# TC100 register map
Vendor: TestCorp; File version: 1.0
Test Device TC100
Registers are 32-bit, read-write, reset 0x0 unless marked. A register's access mark holds for its fields unless they carry their own. Offsets are from the block's base; lines under a group give offsets from that group; [hi:lo] are bit positions; {n}, {i} and the like mark numbered series; 'fields as' and 'values as' point back to an identical list; <NAME> marks a mode.

## Memory map
0x40000000 TIMER0 — General Purpose Timer
0x40020000 DMA — DMA Controller
0x48000000 GPIOA — General-purpose I/O Port A
0x48000400 GPIOB — General-purpose I/O Port B

## TIMER0 — General Purpose Timer
Base 0x40000000
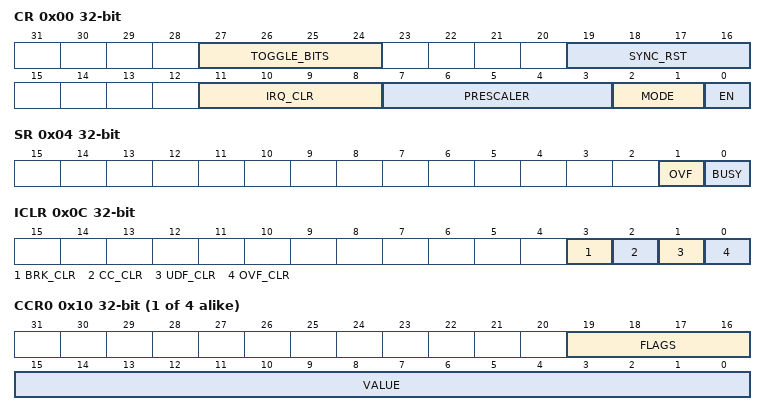
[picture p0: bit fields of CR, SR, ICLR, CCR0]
0x00 CR — Control Register
  [27:24] TOGGLE_BITS write-1-toggles — Toggle Control
  [19:16] SYNC_RST write-0-clears — Synchronous Reset Flags
  [11:8] IRQ_CLR write-1-sets — Interrupt Clear Flags
  [7:3] PRESCALER — Clock Prescaler
  [2:1] MODE — Timer Mode
    0=One-shot mode; 1=Continuous mode; 2=PWM (PWM mode)
  [0] EN write-1-clears — Timer Enable
0x04 SR ro — Status Register
  [1] OVF — Overflow Flag
  [0] BUSY — Timer Busy
0x08 ARR reset 0xFFFFFFFF — Auto-reload Register
  [31:0] RELOAD — Reload Value
0x0C ICLR write-1-clears — Interrupt Clear Register
  [3] BRK_CLR write-0-toggles — Clear break interrupt
  [2] CC_CLR write-0-sets — Clear compare match interrupt
  [1] UDF_CLR — Clear underflow interrupt
  [0] OVF_CLR — Clear overflow interrupt
{0x10+4i} CCR{i} (i=0..3) — Capture/Compare Register {i}
  [19:16] FLAGS write-1-sets — Channel Flags
  [15:0] VALUE — Capture/Compare Value

## DMA — DMA Controller
Base 0x40020000
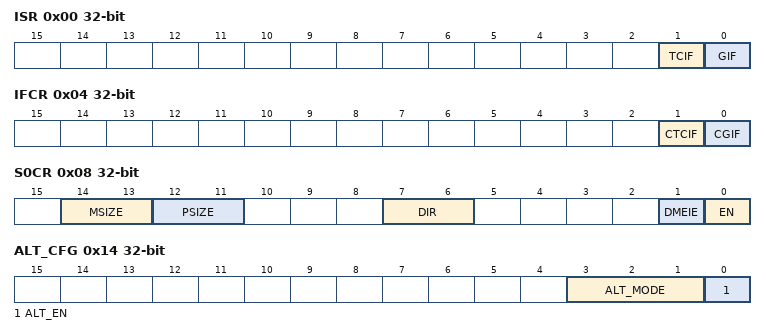
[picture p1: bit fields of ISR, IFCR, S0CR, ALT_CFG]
0x00 ISR ro — Interrupt Status Register
  [1] TCIF — Transfer complete flag
  [0] GIF — Global interrupt flag
0x04 IFCR wo — Interrupt Flag Clear Register
  [1] CTCIF — Clear transfer complete flag
  [0] CGIF — Clear global interrupt flag
0x08 S0CR — Stream 0 Configuration Register
  [14:13] MSIZE — Memory data size
  [12:11] PSIZE — Peripheral data size
    0=Byte (8-bit); 1=HalfWord (16-bit); 2=Word (32-bit)
  [7:6] DIR — Data transfer direction
    0=PeripheralToMemory; 1=MemoryToPeripheral; 2=MemoryToMemory
  [1] DMEIE — Direct Mode Error Interrupt Enable
  [0] EN — Stream Enable
0x0C S0NDTR — Stream 0 Number of Data Register
  [15:0] NDT — Number of data items to transfer
0x10 S0PAR — Stream 0 Peripheral Address Register
  [31:0] PA — Peripheral Address
0x14 S0M0AR — Stream 0 Memory 0 Address Register
  [31:0] M0A — Memory 0 Address
0x14 ALT_CFG — Alternate Configuration Register
  [3:1] ALT_MODE range 1..6 — Alternate mode selection
  [0] ALT_EN — Alternate mode enable

## GPIOA — General-purpose I/O Port A
Base 0x48000000
Same registers: GPIOB 0x48000400
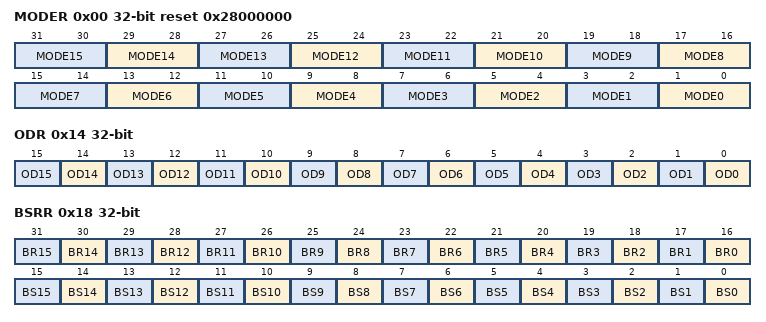
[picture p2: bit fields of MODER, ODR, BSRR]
0x00 MODER reset 0x28000000 — Port Mode Register
  [2n+1:2n] MODE{n} (n=0..15) — Port x configuration bits
    0=Input mode; 1=Output (General purpose output mode); 2=Alternate function mode; 3=Analog mode
0x14 ODR write-1-toggles — Output Data Register
  [n] OD{n} (n=0..15) — Port output data bit {n}
0x18 BSRR wo — Bit Set/Reset Register
  [n+16] BR{n} (n=0..15) — Reset bit {n}
  [n] BS{n} (n=0..15) — Set bit {n}
